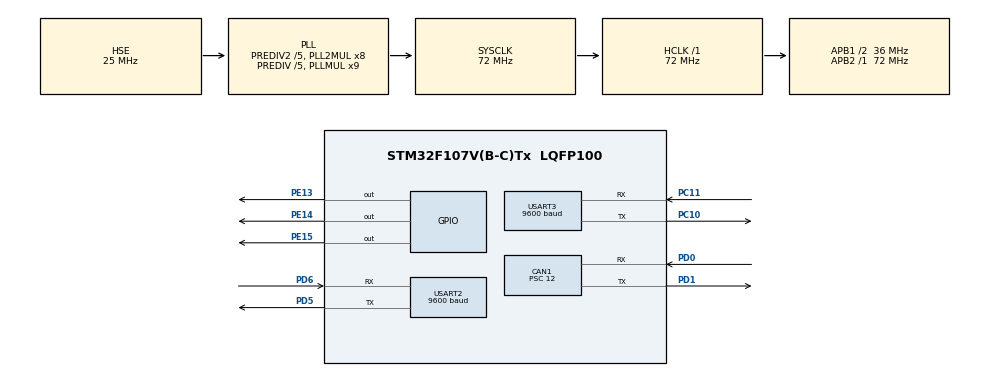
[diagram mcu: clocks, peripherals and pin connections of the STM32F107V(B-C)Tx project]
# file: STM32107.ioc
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CAN1.BS1=CAN_BS1_5TQ
CAN1.BS2=CAN_BS2_6TQ
CAN1.CalculateTimeBit=4000
CAN1.CalculateTimeQuantum=333.33333333333337
CAN1.Mode=CAN_MODE_NORMAL
CAN1.Prescaler=12
Mcu.Family=STM32F1
Mcu.Name=STM32F107V(B-C)Tx
Mcu.Package=LQFP100
NVIC.CAN1_RX0_IRQn=true\:0\:0\:true\:false\:true\:true
NVIC.CAN1_SCE_IRQn=true\:0\:0\:false\:false\:true\:true
NVIC.PriorityGroup=NVIC_PRIORITYGROUP_4
NVIC.TIM2_IRQn=true\:1\:0\:true\:false\:true\:true
NVIC.TIM4_IRQn=true\:2\:0\:true\:false\:true\:true
NVIC.USART2_IRQn=true\:0\:0\:false\:false\:true\:true
OSC_IN.Mode=HSE-External-Oscillator
OSC_IN.Signal=RCC_OSC_IN
OSC_OUT.Mode=HSE-External-Oscillator
OSC_OUT.Signal=RCC_OSC_OUT
PA13.Mode=Serial_Wire
PA13.Signal=SYS_JTMS-SWDIO
PA14.Mode=Serial_Wire
PA14.Signal=SYS_JTCK-SWCLK
PC10.Mode=Asynchronous
PC10.Signal=USART3_TX
PC11.Mode=Asynchronous
PC11.Signal=USART3_RX
PD0.Mode=Master
PD0.Signal=CAN1_RX
PD1.Mode=Master
PD1.Signal=CAN1_TX
PD5.Mode=Asynchronous
PD5.Signal=USART2_TX
PD6.Mode=Asynchronous
PD6.Signal=USART2_RX
PE13.PinState=GPIO_PIN_SET
PE13.Signal=GPIO_Output
PE14.PinState=GPIO_PIN_SET
PE14.Signal=GPIO_Output
PE15.PinState=GPIO_PIN_SET
PE15.Signal=GPIO_Output
ProjectManager.HeapSize=0x200
ProjectManager.StackSize=0x400
ProjectManager.TargetToolchain=MDK-ARM V5
RCC.AHBFreq_Value=72000000
RCC.APB1CLKDivider=RCC_HCLK_DIV2
RCC.APB1Freq_Value=36000000
RCC.APB1TimFreq_Value=72000000
RCC.APB2Freq_Value=72000000
RCC.APB2TimFreq_Value=72000000
RCC.HCLKFreq_Value=72000000
RCC.HSEDivPLL=RCC_HSE_PREDIV_DIV5
RCC.HSE_VALUE=25000000
RCC.PLLMUL=RCC_PLL_MUL9
RCC.PLLSourceVirtual=RCC_PLLSOURCE_HSE
RCC.Prediv1Source=RCC_PREDIV1_SOURCE_PLL2
RCC.Prediv2=RCC_HSE_PREDIV2_DIV5
RCC.SYSCLKFreq_VALUE=72000000
RCC.SYSCLKSource=RCC_SYSCLKSOURCE_PLLCLK
RCC.USBFreq_Value=48000000
TIM2.Period=500-1
TIM2.Prescaler=7200-1
TIM4.Period=20000-1
TIM4.Prescaler=7200-1
USART2.BaudRate=9600
USART2.VirtualMode=VM_ASYNC
USART3.BaudRate=9600
USART3.Mode=MODE_TX
USART3.VirtualMode=VM_ASYNC
VP_TIM2_VS_ClockSourceINT.Mode=Internal
VP_TIM4_VS_ClockSourceINT.Mode=Internal
board=STM32107

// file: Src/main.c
/**
  ******************************************************************************
  * File Name          : main.c
  * Description        : Main program body
  ******************************************************************************
  ** This notice applies to any and all portions of this file
  * that are not between comment pairs USER CODE BEGIN and
  * USER CODE END. Other portions of this file, whether
  * inserted by the user or by software development tools
  * are owned by their respective copyright owners.
  *
  * COPYRIGHT(c) 2018 STMicroelectronics
  *
  * Redistribution and use in source and binary forms, with or without modification,
  * are permitted provided that the following conditions are met:
  *   1. Redistributions of source code must retain the above copyright notice,
  *      this list of conditions and the following disclaimer.
  *   2. Redistributions in binary form must reproduce the above copyright notice,
  *      this list of conditions and the following disclaimer in the documentation
  *      and/or other materials provided with the distribution.
  *   3. Neither the name of STMicroelectronics nor the names of its contributors
  *      may be used to endorse or promote products derived from this software
  *      without specific prior written permission.
  *
  * THIS SOFTWARE IS PROVIDED BY THE COPYRIGHT HOLDERS AND CONTRIBUTORS "AS IS"
  * AND ANY EXPRESS OR IMPLIED WARRANTIES, INCLUDING, BUT NOT LIMITED TO, THE
  * IMPLIED WARRANTIES OF MERCHANTABILITY AND FITNESS FOR A PARTICULAR PURPOSE ARE
  * DISCLAIMED. IN NO EVENT SHALL THE COPYRIGHT HOLDER OR CONTRIBUTORS BE LIABLE
  * FOR ANY DIRECT, INDIRECT, INCIDENTAL, SPECIAL, EXEMPLARY, OR CONSEQUENTIAL
  * DAMAGES (INCLUDING, BUT NOT LIMITED TO, PROCUREMENT OF SUBSTITUTE GOODS OR
  * SERVICES; LOSS OF USE, DATA, OR PROFITS; OR BUSINESS INTERRUPTION) HOWEVER
  * CAUSED AND ON ANY THEORY OF LIABILITY, WHETHER IN CONTRACT, STRICT LIABILITY,
  * OR TORT (INCLUDING NEGLIGENCE OR OTHERWISE) ARISING IN ANY WAY OUT OF THE USE
  * OF THIS SOFTWARE, EVEN IF ADVISED OF THE POSSIBILITY OF SUCH DAMAGE.
  *
  ******************************************************************************
  */

#include "main.h"
#include "stm32f1xx_hal.h"

/* USER CODE BEGIN Includes */
#include  "user_can.h"
#include  "user_time.h"
#include  "user_uart.h"
#include "user_config.h"
#include "sw_timer.h"
/* USER CODE END Includes */

CAN_HandleTypeDef hcan1;

TIM_HandleTypeDef htim2;
TIM_HandleTypeDef htim4;

UART_HandleTypeDef huart2;
UART_HandleTypeDef huart3;

/* USER CODE BEGIN PV */
/* Private variables ---------------------------------------------------------*/

/* USER CODE END PV */

void SystemClock_Config(void);
static void MX_GPIO_Init(void);
static void MX_CAN1_Init(void);
static void MX_USART3_UART_Init(void);
static void MX_TIM2_Init(void);
static void MX_TIM4_Init(void);
static void MX_USART2_UART_Init(void);

/* USER CODE BEGIN PFP */
/* Private function prototypes -----------------------------------------------*/

/* USER CODE END PFP */

int main(void)
{

  /* MCU Configuration----------------------------------------------------------*/

  /* Reset of all peripherals, Initializes the Flash interface and the Systick. */
  HAL_Init();

  /* Configure the system clock */
  SystemClock_Config();

  /* Initialize all configured peripherals */
  MX_GPIO_Init();
  MX_CAN1_Init();
  MX_USART3_UART_Init();
  MX_TIM2_Init();
  MX_TIM4_Init();
  MX_USART2_UART_Init();

  /* USER CODE BEGIN 2 */
	user_uart_init();
	user_time_init();
	user_can_init();
	sw_timer_init();
  /* USER CODE END 2 */

  /* Infinite loop */
  while (1)
  {

  /* USER CODE BEGIN 3 */
#ifdef BUS_CAN_DEBUG
	time_event();
#endif
	can_action_handle();
	sw_timer_handle();
	}

  /* USER CODE END 3 */

}

/** System Clock Configuration
*/
void SystemClock_Config(void)
{

  RCC_OscInitTypeDef RCC_OscInitStruct;
  RCC_ClkInitTypeDef RCC_ClkInitStruct;

    /**Initializes the CPU, AHB and APB busses clocks
    */
  RCC_OscInitStruct.OscillatorType = RCC_OSCILLATORTYPE_HSE;
  RCC_OscInitStruct.HSEState = RCC_HSE_ON;
  RCC_OscInitStruct.HSEPredivValue = RCC_HSE_PREDIV_DIV5;
  RCC_OscInitStruct.HSIState = RCC_HSI_ON;
  RCC_OscInitStruct.Prediv1Source = RCC_PREDIV1_SOURCE_PLL2;
  RCC_OscInitStruct.PLL.PLLState = RCC_PLL_ON;
  RCC_OscInitStruct.PLL.PLLSource = RCC_PLLSOURCE_HSE;
  RCC_OscInitStruct.PLL.PLLMUL = RCC_PLL_MUL9;
  RCC_OscInitStruct.PLL2.PLL2State = RCC_PLL2_ON;
  RCC_OscInitStruct.PLL2.PLL2MUL = RCC_PLL2_MUL8;
  RCC_OscInitStruct.PLL2.HSEPrediv2Value = RCC_HSE_PREDIV2_DIV5;
  if (HAL_RCC_OscConfig(&RCC_OscInitStruct) != HAL_OK)
  {
    _Error_Handler(__FILE__, __LINE__);
  }

    /**Initializes the CPU, AHB and APB busses clocks
    */
  RCC_ClkInitStruct.ClockType = RCC_CLOCKTYPE_HCLK|RCC_CLOCKTYPE_SYSCLK
                              |RCC_CLOCKTYPE_PCLK1|RCC_CLOCKTYPE_PCLK2;
  RCC_ClkInitStruct.SYSCLKSource = RCC_SYSCLKSOURCE_PLLCLK;
  RCC_ClkInitStruct.AHBCLKDivider = RCC_SYSCLK_DIV1;
  RCC_ClkInitStruct.APB1CLKDivider = RCC_HCLK_DIV2;
  RCC_ClkInitStruct.APB2CLKDivider = RCC_HCLK_DIV1;

  if (HAL_RCC_ClockConfig(&RCC_ClkInitStruct, FLASH_LATENCY_2) != HAL_OK)
  {
    _Error_Handler(__FILE__, __LINE__);
  }

    /**Configure the Systick interrupt time
    */
  HAL_SYSTICK_Config(HAL_RCC_GetHCLKFreq()/1000);

    /**Configure the Systick
    */
  HAL_SYSTICK_CLKSourceConfig(SYSTICK_CLKSOURCE_HCLK);

    /**Configure the Systick interrupt time
    */
  __HAL_RCC_PLLI2S_ENABLE();

  /* SysTick_IRQn interrupt configuration */
  HAL_NVIC_SetPriority(SysTick_IRQn, 0, 0);
}

/* CAN1 init function */
static void MX_CAN1_Init(void)
{

  hcan1.Instance = CAN1;
  hcan1.Init.Prescaler = 12;
  hcan1.Init.Mode = CAN_MODE_NORMAL;
  hcan1.Init.SJW = CAN_SJW_1TQ;
  hcan1.Init.BS1 = CAN_BS1_5TQ;
  hcan1.Init.BS2 = CAN_BS2_6TQ;
  hcan1.Init.TTCM = DISABLE;
  hcan1.Init.ABOM = DISABLE;
  hcan1.Init.AWUM = DISABLE;
  hcan1.Init.NART = DISABLE;
  hcan1.Init.RFLM = DISABLE;
  hcan1.Init.TXFP = DISABLE;
  if (HAL_CAN_Init(&hcan1) != HAL_OK)
  {
    _Error_Handler(__FILE__, __LINE__);
  }

}

/* TIM2 init function */
static void MX_TIM2_Init(void)
{

  TIM_ClockConfigTypeDef sClockSourceConfig;
  TIM_MasterConfigTypeDef sMasterConfig;

  htim2.Instance = TIM2;
  htim2.Init.Prescaler = 7200-1;
  htim2.Init.CounterMode = TIM_COUNTERMODE_UP;
  htim2.Init.Period = 500-1;
  htim2.Init.ClockDivision = TIM_CLOCKDIVISION_DIV1;
  htim2.Init.AutoReloadPreload = TIM_AUTORELOAD_PRELOAD_DISABLE;
  if (HAL_TIM_Base_Init(&htim2) != HAL_OK)
  {
    _Error_Handler(__FILE__, __LINE__);
  }

  sClockSourceConfig.ClockSource = TIM_CLOCKSOURCE_INTERNAL;
  if (HAL_TIM_ConfigClockSource(&htim2, &sClockSourceConfig) != HAL_OK)
  {
    _Error_Handler(__FILE__, __LINE__);
  }

  sMasterConfig.MasterOutputTrigger = TIM_TRGO_RESET;
  sMasterConfig.MasterSlaveMode = TIM_MASTERSLAVEMODE_DISABLE;
  if (HAL_TIMEx_MasterConfigSynchronization(&htim2, &sMasterConfig) != HAL_OK)
  {
    _Error_Handler(__FILE__, __LINE__);
  }

}

/* TIM4 init function */
static void MX_TIM4_Init(void)
{

  TIM_ClockConfigTypeDef sClockSourceConfig;
  TIM_MasterConfigTypeDef sMasterConfig;

  htim4.Instance = TIM4;
  htim4.Init.Prescaler = 7200-1;
  htim4.Init.CounterMode = TIM_COUNTERMODE_UP;
  htim4.Init.Period = 20000-1;
  htim4.Init.ClockDivision = TIM_CLOCKDIVISION_DIV1;
  htim4.Init.AutoReloadPreload = TIM_AUTORELOAD_PRELOAD_DISABLE;
  if (HAL_TIM_Base_Init(&htim4) != HAL_OK)
  {
    _Error_Handler(__FILE__, __LINE__);
  }

  sClockSourceConfig.ClockSource = TIM_CLOCKSOURCE_INTERNAL;
  if (HAL_TIM_ConfigClockSource(&htim4, &sClockSourceConfig) != HAL_OK)
  {
    _Error_Handler(__FILE__, __LINE__);
  }

  sMasterConfig.MasterOutputTrigger = TIM_TRGO_RESET;
  sMasterConfig.MasterSlaveMode = TIM_MASTERSLAVEMODE_DISABLE;
  if (HAL_TIMEx_MasterConfigSynchronization(&htim4, &sMasterConfig) != HAL_OK)
  {
    _Error_Handler(__FILE__, __LINE__);
  }

}

/* USART2 init function */
static void MX_USART2_UART_Init(void)
{

  huart2.Instance = USART2;
  huart2.Init.BaudRate = 9600;
  huart2.Init.WordLength = UART_WORDLENGTH_8B;
  huart2.Init.StopBits = UART_STOPBITS_1;
  huart2.Init.Parity = UART_PARITY_NONE;
  huart2.Init.Mode = UART_MODE_TX_RX;
  huart2.Init.HwFlowCtl = UART_HWCONTROL_NONE;
  huart2.Init.OverSampling = UART_OVERSAMPLING_16;
  if (HAL_UART_Init(&huart2) != HAL_OK)
  {
    _Error_Handler(__FILE__, __LINE__);
  }

}

/* USART3 init function */
static void MX_USART3_UART_Init(void)
{

  huart3.Instance = USART3;
  huart3.Init.BaudRate = 9600;
  huart3.Init.WordLength = UART_WORDLENGTH_8B;
  huart3.Init.StopBits = UART_STOPBITS_1;
  huart3.Init.Parity = UART_PARITY_NONE;
  huart3.Init.Mode = UART_MODE_TX;
  huart3.Init.HwFlowCtl = UART_HWCONTROL_NONE;
  huart3.Init.OverSampling = UART_OVERSAMPLING_16;
  if (HAL_UART_Init(&huart3) != HAL_OK)
  {
    _Error_Handler(__FILE__, __LINE__);
  }

}

/** Configure pins as
        * Analog
        * Input
        * Output
        * EVENT_OUT
        * EXTI
*/
static void MX_GPIO_Init(void)
{

  GPIO_InitTypeDef GPIO_InitStruct;

  /* GPIO Ports Clock Enable */
  __HAL_RCC_GPIOE_CLK_ENABLE();
  __HAL_RCC_GPIOA_CLK_ENABLE();
  __HAL_RCC_GPIOC_CLK_ENABLE();
  __HAL_RCC_GPIOD_CLK_ENABLE();

  /*Configure GPIO pin Output Level */
  HAL_GPIO_WritePin(GPIOE, GPIO_PIN_13|GPIO_PIN_14|GPIO_PIN_15, GPIO_PIN_SET);

  /*Configure GPIO pins : PE13 PE14 PE15 */
  GPIO_InitStruct.Pin = GPIO_PIN_13|GPIO_PIN_14|GPIO_PIN_15;
  GPIO_InitStruct.Mode = GPIO_MODE_OUTPUT_PP;
  GPIO_InitStruct.Speed = GPIO_SPEED_FREQ_LOW;
  HAL_GPIO_Init(GPIOE, &GPIO_InitStruct);

}

void _Error_Handler(char * file, int line)
{
  while(1)
  {
  }
}

/************************ (C) COPYRIGHT STMicroelectronics *****END OF FILE****/
